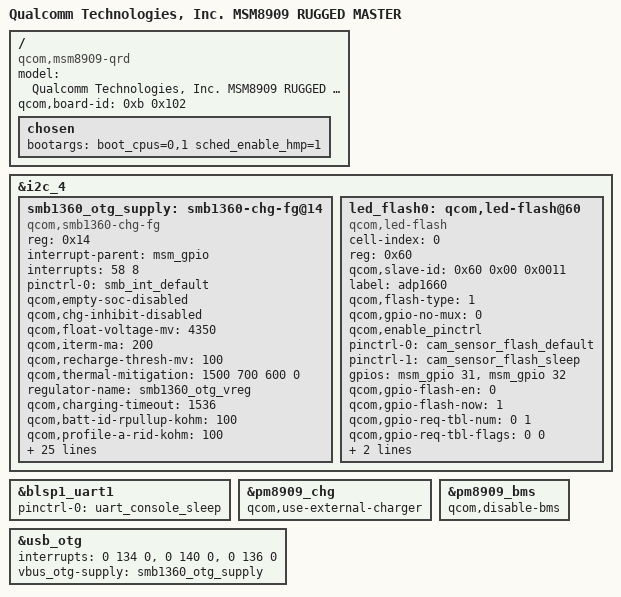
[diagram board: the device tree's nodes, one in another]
/* Copyright (c) 2017, The Linux Foundation. All rights reserved.
 *
 * This program is free software; you can redistribute it and/or modify
 * it under the terms of the GNU General Public License version 2 and
 * only version 2 as published by the Free Software Foundation.
 *
 * This program is distributed in the hope that it will be useful,
 * but WITHOUT ANY WARRANTY; without even the implied warranty of
 * MERCHANTABILITY or FITNESS FOR A PARTICULAR PURPOSE.  See the
 * GNU General Public License for more details.
 */

/dts-v1/;

#include "msm8909-rugged.dtsi"
#include "msm8909-gpu-qhd.dtsi"

/ {
	model = "Qualcomm Technologies, Inc. MSM8909 RUGGED MASTER";
	compatible = "qcom,msm8909-qrd", "qcom,msm8909", "qcom,qrd";
	qcom,board-id= <0xb 0x102>;
	chosen {
		bootargs = "boot_cpus=0,1 sched_enable_hmp=1";
	};
};

&i2c_4 {
smb1360_otg_supply: smb1360-chg-fg@14 {
		compatible = "qcom,smb1360-chg-fg";
		reg = <0x14>;
		interrupt-parent = <&msm_gpio>;
		interrupts = <58 8>;
		pinctrl-names = "default";
		pinctrl-0 = <&smb_int_default>;
		qcom,empty-soc-disabled;
		qcom,chg-inhibit-disabled;
		qcom,float-voltage-mv = <4350>;
		qcom,iterm-ma = <200>;
		qcom,recharge-thresh-mv = <100>;
		qcom,thermal-mitigation = <1500 700 600 0>;
		regulator-name = "smb1360_otg_vreg";

		qcom,charging-timeout = <1536>;
		qcom,batt-id-rpullup-kohm = <100>;
		qcom,profile-a-rid-kohm = <100>; /* <78>; */
		qcom,profile-b-rid-kohm = <28>;

		/* battery capacity */
		qcom,fg-batt-capacity-mah = <4800>;
		qcom,fg-cc-soc-coeff = <0x7b5d>;

		qcom,fg-cutoff-voltage-mv = <3500>;
		qcom,fg-iterm-ma = <100>;
		qcom,fg-ibatt-standby-ma = <200>;
		qcom,fg-cc-to-cv-mv = <4330>;
		qcom,thermistor-c1-coeff = <0x86C2>; /* b=3435k */

		qcom,fg-soc-max = <85>;
		qcom,fg-soc-min = <15>;
		qcom,fg-auto-recharge-soc = <99>;
		qcom,config-hard-thresholds;
		qcom,hot-bat-decidegc = <600>;
		qcom,cold-bat-decidegc = <50>;
		qcom,soft-jeita-supported;
		qcom,warm-bat-decidegc = <450>;
		qcom,cool-bat-decidegc = <0>;
		qcom,warm-bat-mv = <4250>;
		qcom,cool-bat-mv = <4100>;
		qcom,warm-bat-ma = <750>;
		qcom,cool-bat-ma = <750>;

		qcom,otg-batt-curr-limit = <950>;
		qcom,fg-reset-at-pon;
		qcom,fg-reset-thresold-mv = <50>;

		qcom,otp-jeita-cfg;
	};

	led_flash0: qcom,led-flash@60 {
		cell-index = <0>;
		reg = <0x60>;
		qcom,slave-id = <0x60 0x00 0x0011>;
		compatible = "qcom,led-flash";
		label = "adp1660";
		qcom,flash-type = <1>;
		qcom,gpio-no-mux = <0>;
		qcom,enable_pinctrl;
		pinctrl-names = "cam_flash_default", "cam_flash_suspend";
		pinctrl-0 = <&cam_sensor_flash_default>;
		pinctrl-1 = <&cam_sensor_flash_sleep>;
		gpios = <&msm_gpio 31 0>,
		<&msm_gpio 32 0>;
		qcom,gpio-flash-en = <0>;
		qcom,gpio-flash-now = <1>;
		qcom,gpio-req-tbl-num = <0 1>;
		qcom,gpio-req-tbl-flags = <0 0>;
		qcom,gpio-req-tbl-label = "FLASH_EN",
		"FLASH_NOW";
		qcom,cci-master = <0>;
	};
};

&blsp1_uart1 {
	status = "ok";
	pinctrl-names = "default";
	pinctrl-0 = <&uart_console_sleep>;
};

&pm8909_chg {
	status = "ok";
	qcom,use-external-charger;
};

&pm8909_bms {
	status = "ok";
	qcom,disable-bms;
};

&usb_otg {
	interrupts = <0 134 0>,<0 140 0>,<0 136 0>;
	interrupt-names = "core_irq", "async_irq", "phy_irq";

	vbus_otg-supply = <&smb1360_otg_supply>;
};
